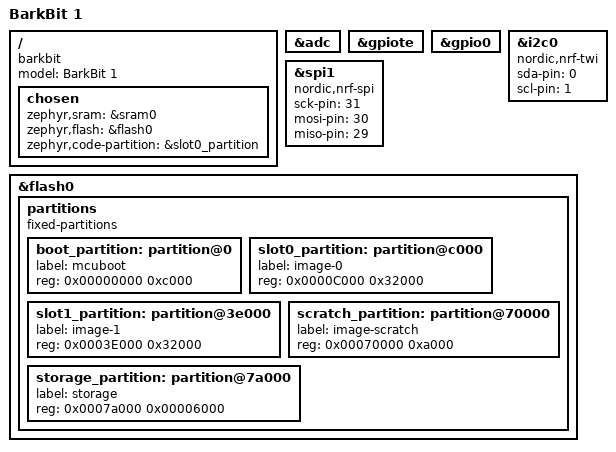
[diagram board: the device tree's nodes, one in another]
/*
 * Copyright (c) 2018 Zelin <zelin@makerdiary.com>
 * Copyright (c) 2018 makerdiary.com.
 *
 * SPDX-License-Identifier: Apache-2.0
 */

/dts-v1/;
#include <nordic/nrf52832_qfaa.dtsi>

/ {
	model = "BarkBit 1";
	compatible = "barkbit";

	chosen {
		// zephyr,console = &rtt0;
		// zephyr,shell-uart = &rtt0;
		// zephyr,uart-mcumgr = &rtt0;
		// zephyr,bt-mon-uart = &rtt0;
		// zephyr,bt-c2h-uart = &rtt0;
		zephyr,sram = &sram0;
		zephyr,flash = &flash0;
		zephyr,code-partition = &slot0_partition;
	};
};

// &hihi {
// 	status = "okay";
// 	//compatible = "nordic,nrf-uart";
// };

/*&uart0 {
	status = "okay";
	compatible = "nordic,nrf-uart";
	current-speed = <115200>;
	tx-pin = <6>;
	rx-pin = <8>;
	rts-pin = <5>;
	cts-pin = <7>;
};*/

&adc {
	status = "okay";
};

&gpiote {
	status = "okay";
};

&gpio0 {
	status = "okay";
};

&i2c0 {
	compatible = "nordic,nrf-twi";
	status = "okay";
	//
	// 4, 5, 6, 7
	sda-pin = <0>;
	scl-pin = <1>;
	
	//sda-pin = <16>;
	//scl-pin = <17>;
	//sda-pin = <26>;
	//scl-pin = <27>;
	/*mma8451q: mma8451q@1c {
		compatible = "nxp,fxos8700","nxp,mma8451q";
		reg = <0x1c>;
		label = "MMA8451Q";
		int1-gpios = <&gpio0 2 GPIO_ACTIVE_LOW>;
		int2-gpios = <&gpio0 3 GPIO_ACTIVE_LOW>;
	};*/
};

&spi1 {
	compatible = "nordic,nrf-spi";
	status = "okay";
	sck-pin = <31>;
	mosi-pin = <30>;
	miso-pin = <29>;
};

&flash0 {
	/*
	 * For more information, see:
	 * http://docs.zephyrproject.org/latest/guides/dts/index.html#flash-partitions
	 */
	partitions {
		compatible = "fixed-partitions";
		#address-cells = <1>;
		#size-cells = <1>;

		boot_partition: partition@0 {
			label = "mcuboot";
			reg = <0x00000000 0xc000>;
		};
		slot0_partition: partition@c000 {
			label = "image-0";
			reg = <0x0000C000 0x32000>;
		};
		slot1_partition: partition@3e000 {
			label = "image-1";
			reg = <0x0003E000 0x32000>;
		};
		scratch_partition: partition@70000 {
			label = "image-scratch";
			reg = <0x00070000 0xa000>;
		};
		storage_partition: partition@7a000 {
			label = "storage";
			reg = <0x0007a000 0x00006000>;
		};
	};
};
